# GD32C231 register map
File version: 1.0
GD32C231 ARM 32-bit Cortex-M23 Microcontroller based device
CPU: CM23 r0p0, little endian, MPU, FPU, 4 interrupt priority bits
Registers are 32-bit, read-write, reset 0x0 unless marked. A register's access mark holds for its fields unless they carry their own. Offsets are from the block's base; lines under a group give offsets from that group; [hi:lo] are bit positions; {n}, {i} and the like mark numbered series; 'fields as' and 'values as' point back to an identical list; <NAME> marks a mode.

## Memory map
0x40000400 TIMER2 size 0x400 — General-level0-timers
0x40002000 TIMER13 size 0x400 — General-level0-timers
0x40002800 RTC size 0x400 — Real time clock
0x40002C00 WWDGT size 0x400 — Window watchdog timer
0x40003000 FWDGT size 0x400 — free watchdog timer
0x40003800 SPI1 size 0x400 — Serial peripheral interface
0x40004400 USART1 size 0x400 — Universal synchronous asynchronous receiver transmitter
0x40004800 USART2 size 0x400 — Universal synchronous asynchronous receiver transmitter
0x40005400 I2C0 size 0x400 — Inter integrated circuit
0x40005800 I2C1 size 0x400
0x40007000 PMU size 0x400 — Power management unit
0x40010000 SYSCFG size 0x400 — System and memory architectur
0x40010400 EXTI size 0x400 — Interrupt / event controller
0x40012400 ADC size 0x400 — Analog-to-digital converter
0x40012C00 TIMER0 size 0x400 — Advanced-timers
0x40013000 SPI0 size 0x400 — Serial Peripheral Interface 0
0x40013800 USART0 size 0x400 — Universal synchronous asynchronous receiver transmitter
0x40014400 TIMER15 size 0x400 — General-level4-timers
0x40014800 TIMER16 size 0x400
0x40015800 DBG size 0x400 — Debug support
0x40017C00 CMP size 0x400 — Comparator
0x40020000 DMA size 0x400 — DMA controller
0x40020800 DMAMUX size 0x400 — DMAMUX controller
0x40021000 RCU size 0x400 — Reset and clock unit
0x40022000 FMC size 0x400 — Flash memory controller
0x40023000 CRC size 0x400 — Cyclic redundancy checks management unit
0x48000000 GPIOA size 0x400 — General-purpose I/Os
0x48000400 GPIOB size 0x400 — General-purpose I/Os
0x48000800 GPIOC size 0x400
0x48000C00 GPIOD size 0x400
0x48001400 GPIOF size 0x400
0xE000E100 NVIC size 0xF00 — Nested Vectored Interrupt Controller

## Interrupts
0 WWDGT
1 RTC_Tamper_Timestamp (RTC)
2 RTC_WAKE (RTC)
3 FMC_GLOBAL (FMC)
5 EXTI0 (EXTI)
6 EXTI01 (EXTI)
7 EXTI2 (EXTI)
8 EXTI3 (EXTI)
9 EXTI4 (EXTI)
10 DMA_Channel0 (DMA)
11 DMA_Channel1 (DMA)
12 DMA_Channel2 (DMA)
13 ADC
14 USART0
15 USART1
16 USART2
17 I2C0_EV (I2C0)
18 I2C0_ER (I2C0)
19 I2C1_EV (I2C1)
20 I2C1_ER (I2C1)
21 SPI0
22 SPI1
23 RTC_Alarm (RTC)
24 EXTI5_9 (EXTI)
25 TIMER0_TRIG_UP_BREAK (TIMER0)
26 TIMER0_CAP (TIMER0)
27 TIMER2
28 TIMER13
29 TIMER15
30 TIMER16
31 EXTI10_15 (EXTI)
33 DMA_MUX (DMAMUX)
34 CMP0 (CMP)
35 CMP1 (CMP)
36 I2C0_WAKE (I2C0)
37 I2C1_WAKE (I2C1)
38 USART0_WAKE (USART0)

## CRC — Cyclic redundancy checks management unit
Base 0x40023000
0x00 DATA reset 0xFFFFFFFF
  [31:0] DATA — CRC calculation result bits
0x04 FDATA — Free data register
  [7:0] FDATA — Free data register bits
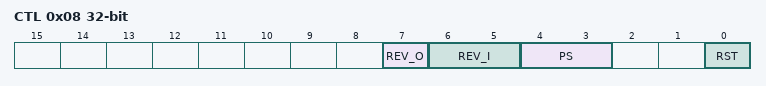
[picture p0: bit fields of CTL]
0x08 CTL — Control register
  [7] REV_O — Reverse output data value in bit order
  [6:5] REV_I — Reverse type for input data
  [4:3] PS — Size of polynomial
  [0] RST — Software writes and reads.
0x10 IDATA reset 0xFFFFFFFF — Initialization data register
  [31:0] IDATA — Configurable initial CRC data value
0x14 POLY reset 0x4C11DB7 — Polynomial register
  [31:0] POLY — User configurable polynomial value

## DBG — Debug support
Base 0x40015800
0x00 ID ro — ID code register
  [31:0] ID_CODE — DBG ID code register
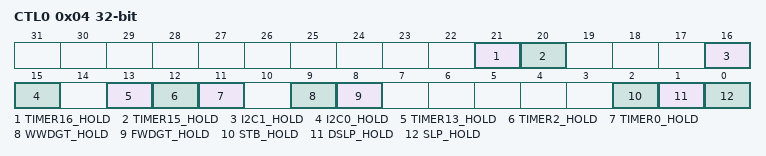
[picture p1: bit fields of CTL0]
0x04 CTL0 — Control register 0
  [21] TIMER16_HOLD — TIMER 16 hold bit
  [20] TIMER15_HOLD — TIMER 15 hold bit
  [16] I2C1_HOLD — I2C1 hold bit
  [15] I2C0_HOLD — I2C0 hold bit
  [13] TIMER13_HOLD — TIMER 13 hold bit
  [12] TIMER2_HOLD — TIMER 2 hold bit
  [11] TIMER0_HOLD — TIMER 0 hold bit
  [9] WWDGT_HOLD — WWDGT hold bit
  [8] FWDGT_HOLD — FWDGT hold bit
  [2] STB_HOLD — Standby mode hold bit
  [1] DSLP_HOLD — Deep-sleep mode hold bit
  [0] SLP_HOLD — Sleep mode hold bit
0x08 CTL1 — Control register 1
  [10] RTC_HOLD — RTC hold bit
